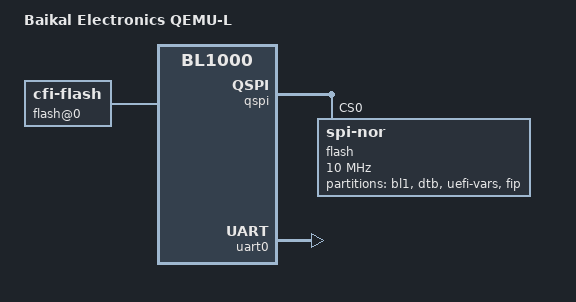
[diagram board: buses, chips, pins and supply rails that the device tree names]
// SPDX-License-Identifier: GPL-2.0
/*
 * Device tree source for Baikal Electronics QEMU-L virtual platform
 * Copyright (C) 2022 Baikal Electronics, JSC
 */

/dts-v1/;

#include "bl1000.dtsi"

/ {
	model = "Baikal Electronics QEMU-L";
	compatible = "baikal,qemu-l", "baikal,bl1000";

	chosen { };

	/*
	 * Device is necessary for UEFI to boot on QEMU,
	 * need to replace it with something later.
	 */
	flash@0 {
		compatible = "cfi-flash";
		reg = <0x0 0x4000000 0x0 0x4000000>;
		bank-width = <0x4>;
	};
};

&qspi {
	num-cs = <4>;
	status = "okay";

	flash@0 {
		compatible = "jedec,spi-nor";
		reg = <0>;
		#address-cells = <1>;
		#size-cells = <1>;
		spi-max-frequency = <10000000>;
		spi-tx-bus-width = <1>;
		spi-rx-bus-width = <1>;
		spi-cs-high;
		status = "okay";

		partitions {
			compatible = "fixed-partitions";
			#address-cells = <1>;
			#size-cells = <1>;

			partition@0 {
				label = "bl1";
				reg = <0x000000 0x40000>;
			};

			partition@40000 {
				label = "dtb";
				reg = <0x040000 0x40000>;
			};

			partition@80000 {
				label = "uefi-vars";
				reg = <0x080000 0xc0000>;
			};

			partition@140000 {
				label = "fip";
				reg = <0x140000 0x6c0000>;
			};
		};
	};
};

&uart0 {
	status = "okay";
};
